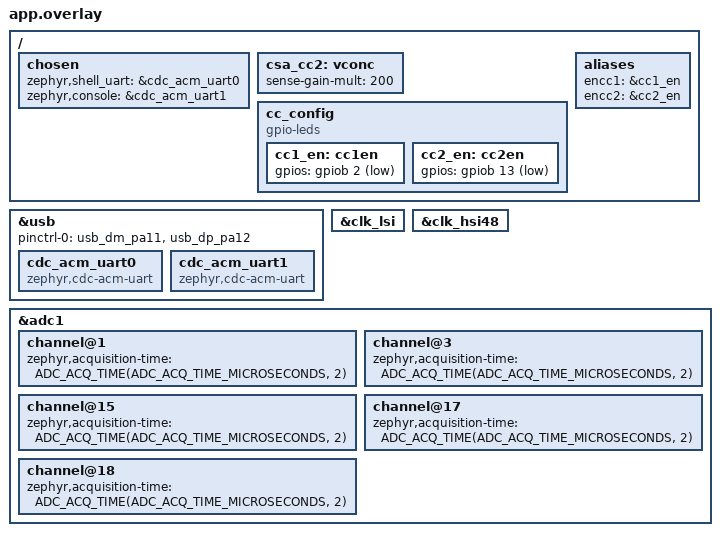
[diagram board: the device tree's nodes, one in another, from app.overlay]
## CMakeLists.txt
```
# Copyright 2023 The ChromiumOS Authors
# Use of this source code is governed by a BSD-style license that can be
# found in the LICENSE file.

set(BOARD google_twinkie_v2)

cmake_minimum_required(VERSION 3.20.5)
find_package(Zephyr REQUIRED HINTS $ENV{ZEPHYR_BASE})

zephyr_include_directories(include)

FILE(GLOB app_sources src/*.c)
target_sources(app PRIVATE ${app_sources})

project(twinkie_v2)
```

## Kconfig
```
# Copyright 2023 The ChromiumOS Authors
# Use of this source code is governed by a BSD-style license that can be
# found in the LICENSE file.

config STM32_UCPD
        bool "USBC TCPC device controller driver"
        depends on SOC_FAMILY_STM32
        default y
	select USE_STM32_LL_BUS
	select USE_STM32_LL_SYSTEM
	select USE_STM32_LL_RCC
	select USE_STM32_LL_DMA
        select USE_STM32_LL_UCPD
	select USE_STM32_LL_USB
	select USE_STM32_HAL_PCD
	select USE_STM32_HAL_PCD_EX
        help
          Enable USBC TCPC support on the STM32 G0, G4, L5, and U5 family of
          processors.

source "Kconfig.zephyr"
```

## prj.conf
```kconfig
# Copyright 2023 The ChromiumOS Authors
# Use of this source code is governed by a BSD-style license that can be
# found in the LICENSE file.

CONFIG_COMPILER_SAVE_TEMPS=y

CONFIG_SMF=y

CONFIG_USB_DEVICE_STACK=y
CONFIG_USB_DEVICE_MANUFACTURER="Google LLC"
CONFIG_USB_DEVICE_PRODUCT="Twinkie V2"
CONFIG_USB_DEVICE_VID=0x18d1
CONFIG_USB_DEVICE_PID=0x5213

CONFIG_USB_DEVICE_STACK=y
CONFIG_USB_COMPOSITE_DEVICE=y
CONFIG_USB_CDC_ACM_RINGBUF_SIZE=512

CONFIG_STDOUT_CONSOLE=y
CONFIG_SERIAL=y
CONFIG_CONSOLE=y
CONFIG_UART_CONSOLE=y
CONFIG_UART_INTERRUPT_DRIVEN=y

CONFIG_PRINTK=y
CONFIG_SHELL=y
CONFIG_SHELL_STACK_SIZE=1024
CONFIG_SHELL_BACKEND_SERIAL=y

CONFIG_THREAD_MONITOR=y
CONFIG_INIT_STACKS=y
CONFIG_BOOT_BANNER=n
CONFIG_THREAD_NAME=y
CONFIG_CBPRINTF_NANO=y

CONFIG_ADC=y
CONFIG_ADC_STM32=y
CONFIG_ADC_SHELL=y
CONFIG_GPIO=y

# A modified version of usb_dc_stm32.c is required.
CONFIG_USB_DC_STM32=n
```

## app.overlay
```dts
/* Copyright 2023 The ChromiumOS Authors
 * Use of this source code is governed by a BSD-style license that can be
 * found in the LICENSE file.
 */

/ {
	chosen {
		zephyr,shell_uart = &cdc_acm_uart0;
		zephyr,console = &cdc_acm_uart1;
	};

        csa_cc2: vconc {
                sense-gain-mult = <200>;
	};

	cc_config {
		compatible = "gpio-leds";
		cc1_en: cc1en {
			gpios = <&gpiob 2 GPIO_ACTIVE_LOW>;
		};

		cc2_en: cc2en {
			gpios = <&gpiob 13 GPIO_ACTIVE_LOW>;
		};
	};

	aliases {
		encc1 = &cc1_en;
		encc2 = &cc2_en;
	};
};

zephyr_udc0: &usb {
	/* Twinkie V2 Command Shell */
	cdc_acm_uart0: cdc_acm_uart0 {
		compatible = "zephyr,cdc-acm-uart";
	};

	/* Twinkie V2 Packet Logging */
	cdc_acm_uart1: cdc_acm_uart1 {
		compatible = "zephyr,cdc-acm-uart";
	};

	pinctrl-0 = <&usb_dm_pa11 &usb_dp_pa12>;
	pinctrl-names = "default";
	status = "okay";
};

&clk_lsi {
	status = "okay";
};

&clk_hsi48 {
	status = "okay";
};

&adc1 {
	channel@1 {
		zephyr,acquisition-time = <ADC_ACQ_TIME(ADC_ACQ_TIME_MICROSECONDS, 2)>;
	};

	channel@3 {
		zephyr,acquisition-time = <ADC_ACQ_TIME(ADC_ACQ_TIME_MICROSECONDS, 2)>;
	};

	channel@15 {
		zephyr,acquisition-time = <ADC_ACQ_TIME(ADC_ACQ_TIME_MICROSECONDS, 2)>;
	};

	channel@17 {
		zephyr,acquisition-time = <ADC_ACQ_TIME(ADC_ACQ_TIME_MICROSECONDS, 2)>;
	};

	channel@18 {
		zephyr,acquisition-time = <ADC_ACQ_TIME(ADC_ACQ_TIME_MICROSECONDS, 2)>;
	};
};
```

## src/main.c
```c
/* Copyright 2023 The ChromiumOS Authors
 * Use of this source code is governed by a BSD-style license that can be
 * found in the LICENSE file.
 */

#include <zephyr/kernel.h>
#include <zephyr/smf.h>
#include <zephyr/drivers/gpio.h>

#include <zephyr/logging/log.h>
#include <zephyr/usb/usb_device.h>
#include <zephyr/device.h>
#include <zephyr/drivers/uart.h>
#include <zephyr/shell/shell.h>

#include "controls.h"
#include "meas.h"
#include "view.h"
#include "model.h"

int main(void)
{
	const struct device *dev_pd_analyzer = DEVICE_DT_GET(DT_CHOSEN(zephyr_console));

	if (usb_enable(NULL)) {
		return -1;
	}

	meas_init();
	controls_init();
	model_init(dev_pd_analyzer);
	view_init();

	return 0;
}
```

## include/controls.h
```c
/* Copyright 2023 The ChromiumOS Authors
 * Use of this source code is governed by a BSD-style license that can be
 * found in the LICENSE file.
 */

#ifndef _CONTROLS_H_
#define _CONTROLS_H_

#include <stdbool.h>

/**
 * @brief Initializes the control module, configure both cc enable pins as active
 *
 * @return 0 on success
 */
int controls_init(void);

/**
 * @brief Enables the cc1 pin
 *
 * @param en true for enable, false for disable
 */
void en_cc1(bool en);

/**
 * @brief Enables the cc2 pin
 *
 * @param en true for enable, false for disable
 */
void en_cc2(bool en);
#endif
```

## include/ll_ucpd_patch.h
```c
/* Copyright 2023 The ChromiumOS Authors
 * Use of this source code is governed by a BSD-style license that can be
 * found in the LICENSE file.
 */

/*
 * Patch file for easy removal when the following issue is resolved:
 * LL Function for checking UCPD RxErr Flag is missing #42
 * https://github.com/STMicroelectronics/STM32CubeG0/issues/42
 */

#include "stm32g0xx_ll_ucpd.h"

#ifndef LL_UCPD_PATCH_H
#define LL_UCPD_PATCH_H

/**
 * @brief  Check if Rx error interrupt
 * @rmtoll SR          RXERR         LL_UCPD_IsActiveFlag_RxErr
 * @param  UCPDx UCPD Instance
 * @retval None
 */
__STATIC_INLINE uint32_t LL_UCPD_IsActiveFlag_RxErr(UCPD_TypeDef const *const UCPDx)
{
	return ((READ_BIT(UCPDx->SR, UCPD_SR_RXERR) == UCPD_SR_RXERR) ? 1UL : 0UL);
}

#endif
```

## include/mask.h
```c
/* Copyright 2023 The ChromiumOS Authors
 * Use of this source code is governed by a BSD-style license that can be
 * found in the LICENSE file.
 */

#ifndef _MASK_H_
#define _MASK_H_

/**
 * @defgroup Bitmask for snooper state
 * Bit positions for the bitmask for setting the role,
 * active CC line, and pull resistors of the Twinkie
 * @{
 */
#define snooper_mask_t uint8_t

#define PULL_RESISTOR_BITS (BIT(0) | BIT(1))
#define SINK_BIT           BIT(2)
#define CC1_CHANNEL_BIT    BIT(3)
#define CC2_CHANNEL_BIT    BIT(4)
/** @} */

#endif
```

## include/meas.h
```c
/* Copyright 2023 The ChromiumOS Authors
 * Use of this source code is governed by a BSD-style license that can be
 * found in the LICENSE file.
 */

#ifndef __MEAS_H__
#define __MEAS_H__

/**
 * @brief Initializes the measurement module, sets up all the adc channels through the device tree
 * binding
 *
 * @return 0 on success
 */
int meas_init(void);

/**
 * @brief Measure the voltage on VBUS
 *
 * @param v pointer where VBUS voltage, in millivolts, is stored
 *
 * @return 0 on success
 */
int meas_vbus_v(int32_t *v);

/**
 * @brief Measure the current on VBUS
 *
 * @param c pointer where VBUS current, in milliamperes, is stored
 *
 * @return 0 on success
 */
int meas_vbus_c(int32_t *c);

/**
 * @brief Measure the voltage on CC1
 *
 * @param v pointer where CC1 voltage, in millivolts, is stored
 *
 * @return 0 on success
 */
int meas_cc1_v(int32_t *v);

/**
 * @brief Measure the voltage on CC2
 *
 * @param v pointer where CC2 voltage, in millivolts, is stored
 *
 * @return 0 on success
 */
int meas_cc2_v(int32_t *v);

/**
 * @brief Measure the current on VCON
 *
 * @param c pointer where VCON current, in milliamperes, is stored
 *
 * @return 0 on success
 */
int meas_vcon_c(int32_t *c);

#endif
```

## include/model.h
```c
/* Copyright 2023 The ChromiumOS Authors
 * Use of this source code is governed by a BSD-style license that can be
 * found in the LICENSE file.
 */

#ifndef _MODEL_H_
#define _MODEL_H_

#include <zephyr/kernel.h>
#include "mask.h"

/**
 * @brief Initializes the snooper model
 *
 * @param dev pointer to the Twinkie device
 *
 * @return 0 on success
 */
int model_init(const struct device *dev);

/**
 * @brief Resets the snooper model
 */
void reset_snooper();

/**
 * @brief Sets the role as source or sink, and set the pull up resistor and active cc line if source
 *
 * @param role_mask a bit mask of the role to be set
 */
void set_role(snooper_mask_t role_mask);

/**
 * @brief Starts or stops the snooper by setting the snoop status
 *
 * @param s true for start, false for stop
 */
void start_snooper(bool s);

/**
 * @brief Sets whether the Twinkie will continuously output data when no pd messages are received
 *
 * @param e true for continuous output, false for output on pd messages only
 */
void set_empty_print(bool e);

/**
 * @brief Sets how fast the twinkie will output data when no pd messages are received
 *
 * @param s true for slow output, false for fast output
 */
void set_sleep_time(uint32_t st);

/**
 * @brief Sets whether twinkie automatically turns off when no receiver is connected.
 *
 * @param s true for auto stop, false for continuous output
 */
void set_auto_stop(bool s);

/**
 * @brief Print to shell the current status of the Twinkie
 *
 * @param ret char array for output of status
 */
void print_status(char *ret, int i);

/**
 * @brief Used only for sharing isr
 */
void ucpd_isr(void);

#endif
```

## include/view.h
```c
/* Copyright 2023 The ChromiumOS Authors
 * Use of this source code is governed by a BSD-style license that can be
 * found in the LICENSE file.
 */

#ifndef _VIEW_H_
#define _VIEW_H_

#include "mask.h"

/**
 * @brief Set the cc line that the snooper is monitoring
 *
 * @param vs bitmask that describes which cc lines should be monitored
 *
 * @return 0 on success
 * @return EIO on failure
 */
int view_set_snoop(snooper_mask_t vs);

/**
 * @brief Records the current cc line connection the Twinkie is detecting
 *
 * @param vc bitmask that describes the cc line that is currently connected
 *
 * @return 0 on success
 * @return EIO on failure
 */
int view_set_connection(snooper_mask_t vc);

/**
 * @brief Returns the value of the cc line currently being snooped.
 *
 * @return bitmask for the current view status
 */
snooper_mask_t get_view_snoop();

/**
 * @brief Initializes the snooper view
 *
 * @param dev pointer to the Twinkie device
 *
 * @return 0 on success
 */
int view_init();

#endif
```

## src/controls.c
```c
/* Copyright 2023 The ChromiumOS Authors
 * Use of this source code is governed by a BSD-style license that can be
 * found in the LICENSE file.
 */

#include <zephyr/kernel.h>
#include <zephyr/drivers/gpio.h>

/* The devicetree node identifier for the cc enable pins. */
#define ENCC1_NODE DT_ALIAS(encc1)
#define ENCC2_NODE DT_ALIAS(encc2)

static const struct gpio_dt_spec encc1 = GPIO_DT_SPEC_GET(ENCC1_NODE, gpios);
static const struct gpio_dt_spec encc2 = GPIO_DT_SPEC_GET(ENCC2_NODE, gpios);

void en_cc1(bool en)
{
	gpio_pin_set_dt(&encc1, en);
}

void en_cc2(bool en)
{
	gpio_pin_set_dt(&encc2, en);
}

int controls_init(void)
{
	int ret;

	if (!device_is_ready(encc1.port)) {
		return -EIO;
	}

	if (!device_is_ready(encc2.port)) {
		return -EIO;
	}

	ret = gpio_pin_configure_dt(&encc1, GPIO_OUTPUT_ACTIVE);
	if (ret < 0) {
		return ret;
	}

	ret = gpio_pin_configure_dt(&encc2, GPIO_OUTPUT_ACTIVE);
	if (ret < 0) {
		return ret;
	}

	return 0;
}
```

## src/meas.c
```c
/* Copyright 2023 The ChromiumOS Authors
 * Use of this source code is governed by a BSD-style license that can be
 * found in the LICENSE file.
 */

#include <stdio.h>
#include <zephyr/kernel.h>
#include <zephyr/drivers/adc.h>
#include <zephyr/drivers/adc/voltage_divider.h>
#include <zephyr/drivers/adc/current_sense_amplifier.h>

/* The devicetree node identifier for the adc aliases. */
#define CC1_V_MEAS_NODE  DT_ALIAS(vcc1)
#define CC2_V_MEAS_NODE  DT_ALIAS(vcc2)
#define VBUS_V_MEAS_NODE DT_ALIAS(vbus)
#define VBUS_C_MEAS_NODE DT_ALIAS(cbus)
#define VCON_C_MEAS_NODE DT_ALIAS(ccon)

static const struct voltage_divider_dt_spec adc_cc1_v =
	VOLTAGE_DIVIDER_DT_SPEC_GET(CC1_V_MEAS_NODE);
static const struct voltage_divider_dt_spec adc_cc2_v =
	VOLTAGE_DIVIDER_DT_SPEC_GET(CC2_V_MEAS_NODE);
static const struct voltage_divider_dt_spec adc_vbus_v =
	VOLTAGE_DIVIDER_DT_SPEC_GET(VBUS_V_MEAS_NODE);
static const struct current_sense_amplifier_dt_spec adc_vbus_c =
	CURRENT_SENSE_AMPLIFIER_DT_SPEC_GET(VBUS_C_MEAS_NODE);
static const struct current_sense_amplifier_dt_spec adc_vcon_c =
	CURRENT_SENSE_AMPLIFIER_DT_SPEC_GET(VCON_C_MEAS_NODE);

int meas_vbus_v(int32_t *v)
{
	int ret;
	int32_t sample_buffer = 0;

	/* Structure defining an ADC sampling sequence */
	struct adc_sequence sequence = {
		.buffer = &sample_buffer,
		/* buffer size in bytes, not number of samples */
		.buffer_size = sizeof(sample_buffer),
		.calibrate = false,
		.oversampling = 8
	};
	adc_sequence_init_dt(&adc_vbus_v.port, &sequence);

	ret = adc_read(adc_vbus_v.port.dev, &sequence);
	if (ret != 0) {
		return ret;
	}

	*v = sample_buffer;
	ret = adc_raw_to_millivolts_dt(&adc_vbus_v.port, v);
	if (ret != 0) {
		return ret;
	}

	ret = voltage_divider_scale_dt(&adc_vbus_v, v);
	if (ret != 0) {
		return ret;
	}

	return 0;
}

int meas_vbus_c(int32_t *c)
{
	int ret;
	int32_t sample_buffer = 0;

	/* Structure defining an ADC sampling sequence */
	struct adc_sequence sequence = {
		.buffer = &sample_buffer,
		/* buffer size in bytes, not number of samples */
		.buffer_size = sizeof(sample_buffer),
		.calibrate = true,
	};
	adc_sequence_init_dt(&adc_vbus_c.port, &sequence);

	ret = adc_read(adc_vbus_c.port.dev, &sequence);
	if (ret != 0) {
		return ret;
	}

	*c = sample_buffer;
	ret = adc_raw_to_millivolts_dt(&adc_vbus_c.port, c);
	if (ret != 0) {
		return ret;
	}

	/* prescaling the voltage offset */
	*c -= adc_vbus_c.port.vref_mv / 2;
	current_sense_amplifier_scale_dt(&adc_vbus_c, c);

	return 0;
}

int meas_cc1_v(int32_t *v)
{
	int ret;
	int32_t sample_buffer = 0;

	/* Structure defining an ADC sampling sequence */
	struct adc_sequence sequence = {
		.buffer = &sample_buffer,
		/* buffer size in bytes, not number of samples */
		.buffer_size = sizeof(sample_buffer),
		.calibrate = true,
	};
	adc_sequence_init_dt(&adc_cc1_v.port, &sequence);

	ret = adc_read(adc_cc1_v.port.dev, &sequence);
	if (ret != 0) {
		return ret;
	}

	*v = sample_buffer;
	ret = adc_raw_to_millivolts_dt(&adc_cc1_v.port, v);
	if (ret != 0) {
		return ret;
	}

	return 0;
}

int meas_cc2_v(int32_t *v)
{
	int ret;
	int32_t sample_buffer = 0;

	/* Structure defining an ADC sampling sequence */
	struct adc_sequence sequence = {
		.buffer = &sample_buffer,
		/* buffer size in bytes, not number of samples */
		.buffer_size = sizeof(sample_buffer),
		.calibrate = true,
	};
	adc_sequence_init_dt(&adc_cc2_v.port, &sequence);

	ret = adc_read(adc_cc2_v.port.dev, &sequence);
	if (ret != 0) {
		return ret;
	}

	*v = sample_buffer;
	ret = adc_raw_to_millivolts_dt(&adc_cc2_v.port, v);
	if (ret != 0) {
		return ret;
	}

	return 0;
}

int meas_vcon_c(int32_t *c)
{
	int ret;
	int32_t sample_buffer = 0;

	/* Structure defining an ADC sampling sequence */
	struct adc_sequence sequence = {
		.buffer = &sample_buffer,
		/* buffer size in bytes, not number of samples */
		.buffer_size = sizeof(sample_buffer),
		.calibrate = true,
	};
	adc_sequence_init_dt(&adc_vcon_c.port, &sequence);

	ret = adc_read(adc_vcon_c.port.dev, &sequence);
	if (ret != 0) {
		return ret;
	}

	*c = sample_buffer;
	ret = adc_raw_to_millivolts_dt(&adc_vcon_c.port, c);
	if (ret != 0) {
		return ret;
	}

	current_sense_amplifier_scale_dt(&adc_vcon_c, c);

	return 0;
}

int meas_init(void)
{
	int ret;

	ret = adc_channel_setup_dt(&adc_cc1_v.port);
	if (ret != 0) {
		return ret;
	}

	ret = adc_channel_setup_dt(&adc_cc2_v.port);
	if (ret != 0) {
		return ret;
	}

	ret = adc_channel_setup_dt(&adc_vbus_v.port);
	if (ret != 0) {
		return ret;
	}

	ret = adc_channel_setup_dt(&adc_vbus_c.port);
	if (ret != 0) {
		return ret;
	}

	ret = adc_channel_setup_dt(&adc_vcon_c.port);
	if (ret != 0) {
		return ret;
	}

	return 0;
}
```

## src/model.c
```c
/* Copyright 2023 The ChromiumOS Authors
 * Use of this source code is governed by a BSD-style license that can be
 * found in the LICENSE file.
 */

#include <stdio.h>
#include <string.h>
#include <zephyr/kernel.h>
#include <zephyr/drivers/gpio.h>
#include <zephyr/drivers/uart.h>
#include <zephyr/sys/ring_buffer.h>

#include <stm32g0xx_ll_bus.h>
#include <stm32g0xx_ll_system.h>
#include <stm32g0xx_ll_dma.h>
#include <stm32g0xx_ll_rcc.h>
#include <stm32g0xx_ll_gpio.h>
#include <stm32g0xx_ll_ucpd.h>

#include "meas.h"
#include "controls.h"
#include "view.h"
#include "model.h"

#include "ll_ucpd_patch.h"

/* STM32 interrupt registers */
#define UCPD_IRQ           8
#define DMA1_CHANNEL1_IRQ  9
#define DMA1_CHANNEL1_PRIO 2
#define UCPD_PRIO          2

/* snooper model thread parameters */
#define MODEL_THREAD_STACK_SIZE 500
#define MODEL_THREAD_PRIORITY   5

/* STM32 UCPD parameters */
static LL_UCPD_InitTypeDef ucpd_params;

/* Byte size of various portions of the packet */
#define MOD_BUFFERS          40
#define PACKET_HEADER_LEN    20
#define PD_SAMPLES           492
#define PACKET_BYTE_SIZE     (PACKET_HEADER_LEN + PD_SAMPLES)
#define MAX_PACKET_XFER_SIZE 64

/* container for information of the type of packet to be sent */
struct packet_type_t {
	uint16_t unused1: 4;
	uint16_t polarity: 2;
	uint16_t lost: 1;
	uint16_t partial: 1;
	uint16_t version: 4;
	uint16_t type: 4;
};

/* container for header of the packet */
struct header_t {
	uint32_t sequence;
	uint16_t cc1_voltage;
	uint16_t cc2_voltage;
	uint16_t vcon_current;
	uint16_t vbus_voltage;
	uint16_t vbus_current;
	struct packet_type_t packet_type;
	uint16_t data_len;
	uint16_t unused;
};

/* container for the entire packet */
struct packet_t {
	struct header_t header;
	uint8_t data[PD_SAMPLES];
};

/* storage for all the information of the current state of the snooper */
static struct model_t {
	const struct device *dev;
	struct packet_t packet;
	uint8_t dma_buffer[PD_SAMPLES];
	k_tid_t tid;
	bool start;
	bool empty_print;
	bool slow_print;
	bool auto_stop;

	uint8_t mod_buff[MOD_BUFFERS][PD_SAMPLES];
	uint16_t mod_size[MOD_BUFFERS];
	struct packet_type_t sop[MOD_BUFFERS];
	uint8_t mw;
	uint8_t mr;
	uint32_t sleep_time;
} model;

K_THREAD_STACK_DEFINE(model_stack_area, MODEL_THREAD_STACK_SIZE);
static struct k_thread model_thread_data;
static int pd_line;

void start_snooper(bool s)
{
	model.start = s;
	if (s) {
		model.packet.header.sequence = 0;
		view_set_snoop(CC1_CHANNEL_BIT | CC2_CHANNEL_BIT);
	} else {
		view_set_snoop(0);
	}
}

void reset_snooper()
{
	memset(&model.mod_buff, 0, MOD_BUFFERS * PD_SAMPLES);
	memset(&model.mod_size, 0, MOD_BUFFERS * sizeof(uint16_t));
	memset(&model.sop, 0, MOD_BUFFERS * sizeof(uint16_t));
	model.mr = 0;
	model.mw = 0;
	model.packet.header.sequence = 0;
}

void set_role(snooper_mask_t role_mask)
{
	if (role_mask & SINK_BIT) {
		LL_UCPD_SetccEnable(UCPD1, LL_UCPD_CCENABLE_CC1CC2);
		LL_UCPD_SetSNKRole(UCPD1);
		return;
	}

	if (role_mask & CC1_CHANNEL_BIT) {
		LL_UCPD_SetccEnable(UCPD1, LL_UCPD_CCENABLE_CC1);
	} else if (role_mask & CC2_CHANNEL_BIT) {
		LL_UCPD_SetccEnable(UCPD1, LL_UCPD_CCENABLE_CC2);
	}
	LL_UCPD_SetSRCRole(UCPD1);

	uint8_t Rp = role_mask & PULL_RESISTOR_BITS;

	switch (Rp) {
	case 0:
		LL_UCPD_SetRpResistor(UCPD1, LL_UCPD_RESISTOR_NONE);
		break;
	case 1:
		LL_UCPD_SetRpResistor(UCPD1, LL_UCPD_RESISTOR_DEFAULT);
		break;
	case 2:
		LL_UCPD_SetRpResistor(UCPD1, LL_UCPD_RESISTOR_1_5A);
		break;
	case 3:
		LL_UCPD_SetRpResistor(UCPD1, LL_UCPD_RESISTOR_3_0A);
	}
}

void set_empty_print(bool e)
{
	model.empty_print = e;
}

void set_sleep_time(uint32_t st)
{
	model.sleep_time = st;
}

void set_auto_stop(bool s)
{
	model.auto_stop = s;
}

void print_status(char *ret, int i)
{
	switch (i) {
	case 0:
		sprintf(ret, "Twinkie status: %s", model.start ? "on" : "off");
		break;
	case 1:
		sprintf(ret, "Current packet number: %i", model.packet.header.sequence);
		break;
	}
}

#define CC_VOLTAGE_LOW  500
#define CC_VOLTAGE_HIGH 2000

static void model_thread(void *arg1, void *arg2, void *arg3)
{
	int32_t vbus_v, vbus_c;
	int32_t vcon_c;
	int32_t cc1_v, cc2_v;
	struct model_t *sm = (struct model_t *)arg1;

	while (1) {
		if (sm->start) {
			sm->packet.header.sequence++;

			if (sm->packet.header.sequence % 10 == 0) {
				meas_vbus_v(&vbus_v);
				meas_vbus_c(&vbus_c);
				meas_cc1_v(&cc1_v);
				meas_cc2_v(&cc2_v);
				meas_vcon_c(&vcon_c);

				/* because the twinkie itself is a port, detecting a
				 * valid connection through the UCPD line will cause
				 * false positives. e.g. if the line being snooped is a
				 * source to source connection and the twinkie is set as
				 * a sink, the twinkie UCPD will incorrectly detect a
				 * valid connection. So the connection has to be
				 * detected using the ADC pins.
				 */
				if ((cc1_v < CC_VOLTAGE_HIGH) && (cc1_v > CC_VOLTAGE_LOW)) {
					/*connect to non-active line if the active line is not set
					 * to view*/
					if (get_view_snoop() & CC1_CHANNEL_BIT) {
						LL_UCPD_SetCCPin(UCPD1, LL_UCPD_CCPIN_CC1);
					} else {
						LL_UCPD_SetCCPin(UCPD1, LL_UCPD_CCPIN_CC2);
					}
					view_set_connection(CC1_CHANNEL_BIT);
					pd_line = 1;
				} else if ((cc2_v < CC_VOLTAGE_HIGH) && (cc2_v > CC_VOLTAGE_LOW)) {
					/*connect to non-active line if the active line is not set
					 * to view*/
					if (get_view_snoop() & CC2_CHANNEL_BIT) {
						LL_UCPD_SetCCPin(UCPD1, LL_UCPD_CCPIN_CC2);
					} else {
						LL_UCPD_SetCCPin(UCPD1, LL_UCPD_CCPIN_CC1);
					}
					view_set_connection(CC2_CHANNEL_BIT);
					pd_line = 2;
				} else {
					view_set_connection(0);
				}
			}
			if (sm->packet.header.sequence % 10 < 8) {
				sm->packet.header.vbus_voltage = vbus_v;
				sm->packet.header.vbus_current = vbus_c;
				sm->packet.header.cc1_voltage = cc1_v;
				sm->packet.header.cc2_voltage = cc2_v;
				sm->packet.header.vcon_current = vcon_c;

				/* put pd message in the packet if any are stored */
				if (sm->mw != sm->mr) {
					sm->packet.header.packet_type = sm->sop[sm->mr];
					sm->packet.header.data_len = sm->mod_size[sm->mr];
					memcpy(sm->packet.data, sm->mod_buff[sm->mr],
					       sm->mod_size[sm->mr]);
					memset((uint8_t *)&sm->sop[sm->mr], 0, sizeof(uint16_t));
					sm->mod_size[sm->mr] = 0;
					memset(sm->mod_buff[sm->mr], 0, PD_SAMPLES);
					sm->mr++;
					if (sm->mr == MOD_BUFFERS) {
						sm->mr = 0;
					}
				}

				if (sm->empty_print || sm->packet.header.data_len != 0) {
					int stop_timer = 0;
					for (int i = 0, w = 0; i < PACKET_BYTE_SIZE; i += w) {
						w = uart_fifo_fill(sm->dev,
								   (const uint8_t *)&sm->packet + i,
								   PACKET_BYTE_SIZE - i);
						if (w <= 0) {
							stop_timer++;
							k_usleep(sm->sleep_time);
							if (stop_timer > 100 && sm->auto_stop) {
								start_snooper(false);
								break;
							}
						}
					}
				}
				memset(sm->packet.data, 0, PD_SAMPLES);
				sm->packet.header.data_len = 0;
			}
		}
		if (sm->mw == sm->mr) {
			k_usleep(sm->sleep_time);
		}
	}
}

#define MY_DEV_IRQ   12
#define MY_DEV_PRIO  2
#define MY_ISR_ARG   NULL
#define MY_IRQ_FLAGS 0

void ucpd_isr(void)
{
	struct model_t *sm = &model;

	/* TypeCEvent flag currently not used */
	if (LL_UCPD_IsActiveFlag_TypeCEventCC1(UCPD1) ||
	    LL_UCPD_IsActiveFlag_TypeCEventCC2(UCPD1)) {
		LL_UCPD_ClearFlag_TypeCEventCC1(UCPD1);
		LL_UCPD_ClearFlag_TypeCEventCC2(UCPD1);
	}

	if (LL_UCPD_IsActiveFlag_RxErr(UCPD1)) {
		LL_DMA_DisableChannel(DMA1, LL_DMA_CHANNEL_1);
		LL_DMA_SetDataLength(DMA1, LL_DMA_CHANNEL_1, PD_SAMPLES);
		memcpy(sm->mod_buff[sm->mw], sm->dma_buffer, PD_SAMPLES);
		memset(sm->dma_buffer, 0, PD_SAMPLES);
		sm->mod_size[sm->mw] = LL_UCPD_ReadRxPaySize(UCPD1);
		sm->sop[sm->mr].type = LL_UCPD_ReadRxOrderSet(UCPD1);
		sm->sop[sm->mw].polarity = pd_line;
		sm->sop[sm->mw].partial = true;
		sm->mw++;
		if (sm->mw == MOD_BUFFERS) {
			sm->mw = 0;
		}
		LL_DMA_EnableChannel(DMA1, LL_DMA_CHANNEL_1);
		k_wakeup(sm->tid);
	}

	if (LL_UCPD_IsActiveFlag_RxMsgEnd(UCPD1)) {
		LL_DMA_DisableChannel(DMA1, LL_DMA_CHANNEL_1);
		LL_DMA_SetDataLength(DMA1, LL_DMA_CHANNEL_1, PD_SAMPLES);
		memcpy(sm->mod_buff[sm->mw], sm->dma_buffer, PD_SAMPLES);
		memset(sm->dma_buffer, 0, PD_SAMPLES);
		sm->mod_size[sm->mw] = LL_UCPD_ReadRxPaySize(UCPD1);
		sm->sop[sm->mr].type = LL_UCPD_ReadRxOrderSet(UCPD1);
		sm->sop[sm->mw].polarity = pd_line;
		sm->sop[sm->mw].partial = false;
		sm->mw++;
		if (sm->mw == MOD_BUFFERS) {
			sm->mw = 0;
		}
		LL_DMA_EnableChannel(DMA1, LL_DMA_CHANNEL_1);
		k_wakeup(sm->tid);
		LL_UCPD_ClearFlag_RxMsgEnd(UCPD1);
	}
}

static void update_stm32g0x_cc_line(void)
{
	SYSCFG->CFGR1 |= SYSCFG_CFGR1_UCPD1_STROBE_Msk;
}

enum pd_cc_t {
	PD_OFF,
	PD_BOTH,
	PD_CC1,
	PD_CC2
};

static void pd_on_cc(enum pd_cc_t p)
{
	switch (p) {
	case PD_OFF:
		LL_UCPD_TypeCDetectionCC1Disable(UCPD1);
		LL_UCPD_TypeCDetectionCC2Disable(UCPD1);
		break;
	case PD_BOTH:
		LL_UCPD_TypeCDetectionCC1Enable(UCPD1);
		LL_UCPD_TypeCDetectionCC2Enable(UCPD1);
		break;
	case PD_CC1:
		LL_UCPD_TypeCDetectionCC2Disable(UCPD1);
		LL_UCPD_TypeCDetectionCC1Enable(UCPD1);
		break;
	case PD_CC2:
		LL_UCPD_TypeCDetectionCC1Disable(UCPD1);
		LL_UCPD_TypeCDetectionCC2Enable(UCPD1);
		break;
	}
}

int model_init(const struct device *dev)
{
	int ret;

	model.dev = dev;
	model.mw = 0;
	model.mr = 0;

	update_stm32g0x_cc_line();

	/** Configure CC pins */

	/* Set PIN A8 as analog */
	LL_GPIO_SetPinMode(GPIOA, LL_GPIO_PIN_8, LL_GPIO_MODE_ANALOG);

	/* Set PIN B15 as analog */
	LL_GPIO_SetPinMode(GPIOB, LL_GPIO_PIN_15, LL_GPIO_MODE_ANALOG);

	/** Configure DMA */

	/* DMA CLOCK */
	LL_AHB1_GRP1_EnableClock(LL_AHB1_GRP1_PERIPH_DMA1);

	LL_DMA_DisableChannel(DMA1, LL_DMA_CHANNEL_1);

	LL_DMA_ConfigTransfer(DMA1, LL_DMA_CHANNEL_1, LL_DMA_DIRECTION_PERIPH_TO_MEMORY);

	/* DMA from UCPD RXDR register */
	LL_DMA_ConfigAddresses(DMA1, LL_DMA_CHANNEL_1, (uint32_t)&UCPD1->RXDR,
			       (uint32_t)model.dma_buffer, LL_DMA_DIRECTION_PERIPH_TO_MEMORY);

	LL_DMA_SetMode(DMA1, LL_DMA_CHANNEL_1, LL_DMA_MODE_NORMAL);

	LL_DMA_SetPeriphIncMode(DMA1, LL_DMA_CHANNEL_1, LL_DMA_PERIPH_NOINCREMENT);

	LL_DMA_SetMemoryIncMode(DMA1, LL_DMA_CHANNEL_1, LL_DMA_MEMORY_INCREMENT);

	LL_DMA_SetPeriphSize(DMA1, LL_DMA_CHANNEL_1, LL_DMA_PDATAALIGN_BYTE);

	LL_DMA_SetMemorySize(DMA1, LL_DMA_CHANNEL_1, LL_DMA_MDATAALIGN_BYTE);

	LL_DMA_SetChannelPriorityLevel(DMA1, LL_DMA_CHANNEL_1, LL_DMA_PRIORITY_VERYHIGH);

	LL_DMA_SetDataLength(DMA1, LL_DMA_CHANNEL_1, PD_SAMPLES);

	LL_DMA_SetPeriphRequest(DMA1, LL_DMA_CHANNEL_1, LL_DMAMUX_REQ_UCPD1_RX);

	LL_DMA_EnableChannel(DMA1, LL_DMA_CHANNEL_1);

	model.packet.header.sequence = 0;

	/** Configure UCPD */

	ucpd_params.psc_ucpdclk = 0;
	ucpd_params.transwin = 7;
	ucpd_params.IfrGap = 16;
	ucpd_params.HbitClockDiv = 26;

	/*
	 * The UCPD port is disabled in the LL_UCPD_Init function
	 *
	 * NOTE: For proper Power Management operation, this function
	 *       should not be used because it circumvents the zephyr
	 *       clock API. Instead, DTS clock settings and the zephyr
	 *       clock API should be used to enable clocks.
	 */
	ret = LL_UCPD_Init(UCPD1, &ucpd_params);
	if (ret == SUCCESS) {
		/* ORDSET */
		LL_UCPD_SetRxOrderSet(UCPD1, LL_UCPD_ORDERSET_SOP | LL_UCPD_ORDERSET_SOP1 |
						     LL_UCPD_ORDERSET_SOP2 |
						     LL_UCPD_ORDERSET_HARDRST |
						     LL_UCPD_ORDERSET_CABLERST);

		/* ENABLE DMA */
		LL_UCPD_RxDMAEnable(UCPD1);

		/* Enable UCPD port */
		LL_UCPD_Enable(UCPD1);
		start_snooper(false);

		pd_on_cc(PD_BOTH);
		update_stm32g0x_cc_line();

		LL_UCPD_EnableIT_RxNE(UCPD1);

		LL_UCPD_EnableIT_TypeCEventCC1(UCPD1);
		LL_UCPD_EnableIT_TypeCEventCC2(UCPD1);
		LL_UCPD_ClearFlag_TypeCEventCC1(UCPD1);
		LL_UCPD_ClearFlag_TypeCEventCC2(UCPD1);

		LL_UCPD_SetccEnable(UCPD1, LL_UCPD_CCENABLE_CC1CC2);

		LL_UCPD_EnableIT_RxMsgEnd(UCPD1);
		LL_UCPD_ClearFlag_RxMsgEnd(UCPD1);

		LL_UCPD_RxEnable(UCPD1);
	} else {
		return -EIO;
	}

	LL_UCPD_SetSNKRole(UCPD1);

	en_cc1(true);
	en_cc2(true);

	set_auto_stop(true);
	set_empty_print(true);
	set_sleep_time(500);

	model.tid = k_thread_create(&model_thread_data, model_stack_area,
				    K_THREAD_STACK_SIZEOF(model_stack_area), model_thread, &model,
				    NULL, NULL, MODEL_THREAD_PRIORITY, 0, K_NO_WAIT);

	return 0;
}
```

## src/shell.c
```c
/* Copyright 2023 The ChromiumOS Authors
 * Use of this source code is governed by a BSD-style license that can be
 * found in the LICENSE file.
 */

#include <stdlib.h>
#include <zephyr/kernel.h>
#include <zephyr/usb/usb_device.h>
#include <zephyr/device.h>
#include <zephyr/drivers/uart.h>
#include <zephyr/shell/shell.h>
#include <zephyr/drivers/usb/usb_dc.h>

#include "view.h"
#include "meas.h"
#include "model.h"
#include "mask.h"

static int cmd_meas_cc2(const struct shell *shell, size_t argc, char **argv)
{
	int32_t out;

	if (argc == 2 && *argv[1] == 'c') {
		meas_vcon_c(&out);
		shell_print(shell, "current of cc2: %i", out);
	} else {
		meas_cc2_v(&out);
		shell_print(shell, "voltage of cc2: %i", out);
	}

	return 0;
}

static int cmd_meas_vb(const struct shell *shell, size_t argc, char **argv)
{
	int32_t out;

	if (argc == 2 && *argv[1] == 'c') {
		meas_vbus_c(&out);
		shell_print(shell, "current of vbus: %i", out);
	} else {
		meas_vbus_v(&out);
		shell_print(shell, "voltage of vbus: %i", out);
	}

	return 0;
}

static int cmd_meas_cc1(const struct shell *shell, size_t argc, char **argv)
{
	int32_t out;

	meas_cc1_v(&out);
	shell_print(shell, "voltage of cc1: %i", out);

	return 0;
}

SHELL_STATIC_SUBCMD_SET_CREATE(sub_meas, SHELL_CMD(cc1, NULL, "Print cc1 voltage.", cmd_meas_cc1),
			       SHELL_CMD(cc2, NULL, "Print cc2 voltage or current.", cmd_meas_cc2),
			       SHELL_CMD(vb, NULL, "Print vbus voltage or current.", cmd_meas_vb),
			       SHELL_SUBCMD_SET_END);

SHELL_CMD_REGISTER(meas, &sub_meas, "Reads current or voltage of the selected line", NULL);

static int cmd_version(const struct shell *shell, size_t argc, char **argv)
{
	ARG_UNUSED(argc);
	ARG_UNUSED(argv);

	shell_print(shell, "Twinkie version 2.2.2");

	return 0;
}

SHELL_CMD_REGISTER(version, NULL, "Show Twinkie version", cmd_version);

static int cmd_reset(const struct shell *shell, size_t argc, char **argv)
{
	start_snooper(false);
	reset_snooper();
	usb_dc_reset();

	start_snooper(true);
	return 0;
}

SHELL_CMD_REGISTER(reset, NULL, "Resets the Twinkie device", cmd_reset);

static int cmd_snoop(const struct shell *shell, size_t argc, char **argv)
{
	if (argc >= 2) {
		switch (*argv[1]) {
		case '0':
			view_set_snoop(0);
			break;
		case '1':
			view_set_snoop(CC1_CHANNEL_BIT);
			break;
		case '2':
			view_set_snoop(CC2_CHANNEL_BIT);
			break;
		case '3':
			view_set_snoop(CC1_CHANNEL_BIT | CC2_CHANNEL_BIT);
		}
	}

	return 0;
}

SHELL_CMD_REGISTER(snoop, NULL, "Sets the snoop CC line, 0 for neither, 3 for both", cmd_snoop);

static int cmd_start(const struct shell *shell, size_t argc, char **argv)
{
	start_snooper(true);
	return 0;
}
SHELL_CMD_REGISTER(start, NULL, "Start snooper", cmd_start);

static int cmd_stop(const struct shell *shell, size_t argc, char **argv)
{
	usb_dc_reset();
	start_snooper(false);
	return 0;
}
SHELL_CMD_REGISTER(stop, NULL, "Stop snooper", cmd_stop);

static int cmd_role(const struct shell *shell, size_t argc, char **argv, void *data)
{
	snooper_mask_t pull_mask = (uint32_t)data;

	set_role(pull_mask);

	return 0;
}

SHELL_SUBCMD_DICT_SET_CREATE(role_options, cmd_role, (sink, SINK_BIT, "sink"),
			     (source, 0, "source"));

SHELL_CMD_REGISTER(role, &role_options, "Sets role as sink or source", cmd_role);

static int cmd_cc1_pull(const struct shell *shell, size_t argc, char **argv, void *data)
{
	snooper_mask_t pull_mask = (uint32_t)data;

	set_role(pull_mask & CC1_CHANNEL_BIT);

	return 0;
}

static int cmd_cc2_pull(const struct shell *shell, size_t argc, char **argv, void *data)
{
	snooper_mask_t pull_mask = (uint32_t)data;

	set_role(pull_mask & CC2_CHANNEL_BIT);

	return 0;
}

SHELL_SUBCMD_DICT_SET_CREATE(cc1_options, cmd_cc1_pull, (rd, 0, "resistor disconnected"),
			     (ru, 1, "default resistor"), (r1, 2, "1.5A resistor"),
			     (r3, 3, "3A resistor"));

SHELL_SUBCMD_DICT_SET_CREATE(cc2_options, cmd_cc2_pull, (rd, 0, "resistor disconnected"),
			     (ru, 1, "default resistor"), (r1, 2, "1.5A resistor"),
			     (r3, 3, "3A resistor"));

SHELL_STATIC_SUBCMD_SET_CREATE(
	sub_rpull, SHELL_CMD(cc1, &cc1_options, "Sets pull resistor on cc1", cmd_cc1_pull),
	SHELL_CMD(cc2, &cc2_options, "Sets pull resistor on cc2", cmd_cc2_pull),
	SHELL_SUBCMD_SET_END);

SHELL_CMD_REGISTER(rpull, &sub_rpull, "Place pull resistor", NULL);

static int cmd_output(const struct shell *shell, size_t argc, char **argv, void *data)
{
	bool p = (int)data;

	set_empty_print(p);

	return 0;
}

SHELL_SUBCMD_DICT_SET_CREATE(output_options, cmd_output, (cont, true, "continuous output"),
			     (pd_only, false, "output only on receiving pd messages"));

SHELL_CMD_REGISTER(output, &output_options,
		   "Sets console output as continuous or only on receiving PD messages",
		   cmd_output);

static int cmd_auto_stop(const struct shell *shell, size_t argc, char **argv, void *data)
{
	bool p = (bool)data;

	set_auto_stop(p);

	return 0;
}

SHELL_SUBCMD_DICT_SET_CREATE(cmd_auto_stop_options, cmd_auto_stop,
			     (on, true, "twinkie turns off when no reciever is connected"),
			     (off, false,
			      "twinkie continues sending even when there is no response "
			      "from host (WARNING: may cause data corruption or desync)"));

SHELL_CMD_REGISTER(auto_stop, &cmd_auto_stop_options,
		   "Sets to automatically turn off when no valid receiver is connected",
		   cmd_auto_stop);

static int cmd_sleep_time(const struct shell *shell, size_t argc, char **argv, void *data)
{
	if (argc == 2) {
		set_sleep_time(atoi(argv[1]));
		shell_print(shell, "%d", atoi(argv[1]));
	}

	return 0;
}

SHELL_CMD_REGISTER(sleep_time, NULL,
		   "Sets console output as continuous or only on receiving PD messages",
		   cmd_sleep_time);

static int cmd_status(const struct shell *shell, size_t argc, char **argv)
{

	char p[50];

	print_status(p, 0);
	shell_print(shell, "%s", p);
	print_status(p, 1);
	shell_print(shell, "%s", p);

	return 0;
}

SHELL_CMD_REGISTER(status, NULL, "Print the twinkie status", cmd_status);
```

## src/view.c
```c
/* Copyright 2023 The ChromiumOS Authors
 * Use of this source code is governed by a BSD-style license that can be
 * found in the LICENSE file.
 */

#include <zephyr/kernel.h>
#include <zephyr/smf.h>
#include <zephyr/drivers/gpio.h>

#include <zephyr/logging/log.h>
#include <zephyr/usb/usb_device.h>
#include <zephyr/device.h>
#include <zephyr/drivers/uart.h>
#include <zephyr/shell/shell.h>

#include "controls.h"
#include "meas.h"
#include "view.h"
#include "model.h"

LOG_MODULE_REGISTER(main);

#define DEBUG 1

/* The devicetree node identifier for the led aliases. */
#define LED0_NODE DT_ALIAS(led0)
#define LED1_NODE DT_ALIAS(led1)
#define LED2_NODE DT_ALIAS(led2)

/* various flags for the current state of the snooper */
#define FLAGS_SNOOP0         0
#define FLAGS_SNOOP1         1
#define FLAGS_SNOOP2         2
#define FLAGS_SNOOP3         3
#define FLAGS_NO_CONNECTION  4
#define FLAGS_CC1_CONNECTION 5
#define FLAGS_CC2_CONNECTION 6

static const struct gpio_dt_spec led0 = GPIO_DT_SPEC_GET(LED0_NODE, gpios);
static const struct gpio_dt_spec led1 = GPIO_DT_SPEC_GET(LED1_NODE, gpios);
static const struct gpio_dt_spec led2 = GPIO_DT_SPEC_GET(LED2_NODE, gpios);

static const struct smf_state view_states[];

enum led_t {
	LED_OFF,
	LED_RED,
	LED_GREEN,
	LED_BLUE
};
enum view_state_t {
	SNOOP0,
	SNOOP1,
	SNOOP2,
	SNOOP3
};

struct view_obj_t {
	struct smf_ctx ctx;
	k_timeout_t timeout;
	bool toggle;
	atomic_t flags;
} view_obj;

snooper_mask_t get_view_snoop()
{
	if (atomic_test_bit(&view_obj.flags, FLAGS_SNOOP0)) {
		return 0;
	}
	if (atomic_test_bit(&view_obj.flags, FLAGS_SNOOP1)) {
		return CC1_CHANNEL_BIT;
	}
	if (atomic_test_bit(&view_obj.flags, FLAGS_SNOOP2)) {
		return CC2_CHANNEL_BIT;
	}
	if (atomic_test_bit(&view_obj.flags, FLAGS_SNOOP3)) {
		return (CC1_CHANNEL_BIT | CC2_CHANNEL_BIT);
	}
	return 0;
}

int view_set_connection(snooper_mask_t vc)
{
	switch (vc) {
	case 0:
		atomic_clear_bit(&view_obj.flags, FLAGS_CC1_CONNECTION);
		atomic_clear_bit(&view_obj.flags, FLAGS_CC2_CONNECTION);
		atomic_set_bit(&view_obj.flags, FLAGS_NO_CONNECTION);
		break;
	case CC1_CHANNEL_BIT:
		atomic_clear_bit(&view_obj.flags, FLAGS_NO_CONNECTION);
		atomic_clear_bit(&view_obj.flags, FLAGS_CC2_CONNECTION);
		atomic_set_bit(&view_obj.flags, FLAGS_CC1_CONNECTION);
		break;
	case CC2_CHANNEL_BIT:
		atomic_clear_bit(&view_obj.flags, FLAGS_NO_CONNECTION);
		atomic_clear_bit(&view_obj.flags, FLAGS_CC1_CONNECTION);
		atomic_set_bit(&view_obj.flags, FLAGS_CC2_CONNECTION);
		break;
	default:
		return -EIO;
	}
	return 0;
}

int view_set_snoop(snooper_mask_t vs)
{
	switch (vs) {
	case 0:
		atomic_clear_bit(&view_obj.flags, FLAGS_SNOOP1);
		atomic_clear_bit(&view_obj.flags, FLAGS_SNOOP2);
		atomic_clear_bit(&view_obj.flags, FLAGS_SNOOP3);
		atomic_set_bit(&view_obj.flags, FLAGS_SNOOP0);
		break;
	case CC1_CHANNEL_BIT:
		atomic_clear_bit(&view_obj.flags, FLAGS_SNOOP0);
		atomic_clear_bit(&view_obj.flags, FLAGS_SNOOP2);
		atomic_clear_bit(&view_obj.flags, FLAGS_SNOOP3);
		atomic_set_bit(&view_obj.flags, FLAGS_SNOOP1);
		break;
	case CC2_CHANNEL_BIT:
		atomic_clear_bit(&view_obj.flags, FLAGS_SNOOP0);
		atomic_clear_bit(&view_obj.flags, FLAGS_SNOOP1);
		atomic_clear_bit(&view_obj.flags, FLAGS_SNOOP3);
		atomic_set_bit(&view_obj.flags, FLAGS_SNOOP2);
		break;
	case (CC1_CHANNEL_BIT | CC2_CHANNEL_BIT):
		atomic_clear_bit(&view_obj.flags, FLAGS_SNOOP0);
		atomic_clear_bit(&view_obj.flags, FLAGS_SNOOP1);
		atomic_clear_bit(&view_obj.flags, FLAGS_SNOOP2);
		atomic_set_bit(&view_obj.flags, FLAGS_SNOOP3);
		break;
	default:
		return -EIO;
	}

	view_set_connection(0);
	return 0;
}

static void set_led(enum led_t led)
{
	switch (led) {
	case LED_OFF:
		gpio_pin_set_dt(&led0, 0);
		gpio_pin_set_dt(&led1, 0);
		gpio_pin_set_dt(&led2, 0);
		break;
	case LED_RED:
		gpio_pin_set_dt(&led0, 1);
		gpio_pin_set_dt(&led1, 0);
		gpio_pin_set_dt(&led2, 0);
		break;
	case LED_GREEN:
		gpio_pin_set_dt(&led0, 0);
		gpio_pin_set_dt(&led1, 1);
		gpio_pin_set_dt(&led2, 0);
		break;
	case LED_BLUE:
		gpio_pin_set_dt(&led0, 0);
		gpio_pin_set_dt(&led1, 0);
		gpio_pin_set_dt(&led2, 1);
		break;
	}
}

static void snoop0_entry(void *o)
{
	struct view_obj_t *vo = (struct view_obj_t *)o;

	set_led(LED_OFF);
	vo->timeout = K_MSEC(1000);
}

static void snoop0_run(void *o)
{
	struct view_obj_t *vo = (struct view_obj_t *)o;

	if (atomic_test_bit(&vo->flags, FLAGS_SNOOP1)) {
		smf_set_state(SMF_CTX(vo), &view_states[SNOOP1]);
	} else if (atomic_test_bit(&vo->flags, FLAGS_SNOOP2)) {
		smf_set_state(SMF_CTX(vo), &view_states[SNOOP2]);
	} else if (atomic_test_bit(&vo->flags, FLAGS_SNOOP3)) {
		smf_set_state(SMF_CTX(vo), &view_states[SNOOP3]);
	}
}

static void snoop0_exit(void *o)
{
}

static void snoop1_entry(void *o)
{
	struct view_obj_t *vo = (struct view_obj_t *)o;

	vo->timeout = K_MSEC(1000);
}

static void snoop1_run(void *o)
{
	struct view_obj_t *vo = (struct view_obj_t *)o;

	if (atomic_test_bit(&vo->flags, FLAGS_SNOOP0)) {
		smf_set_state(SMF_CTX(vo), &view_states[SNOOP0]);
	} else if (atomic_test_bit(&vo->flags, FLAGS_SNOOP2)) {
		smf_set_state(SMF_CTX(vo), &view_states[SNOOP2]);
	} else if (atomic_test_bit(&vo->flags, FLAGS_SNOOP3)) {
		smf_set_state(SMF_CTX(vo), &view_states[SNOOP3]);
	} else if (atomic_test_bit(&vo->flags, FLAGS_NO_CONNECTION)) {
		if (vo->toggle) {
			set_led(LED_BLUE);
			vo->toggle = false;
		} else {
			set_led(LED_OFF);
			vo->toggle = true;
		}
	} else if (atomic_test_bit(&vo->flags, FLAGS_CC1_CONNECTION)) {
		set_led(LED_GREEN);
	} else if (atomic_test_bit(&vo->flags, FLAGS_CC2_CONNECTION)) {
		set_led(LED_RED);
	}
}

static void snoop1_exit(void *o)
{
	set_led(LED_OFF);
}

static void snoop2_entry(void *o)
{
	struct view_obj_t *vo = (struct view_obj_t *)o;

	vo->timeout = K_MSEC(500);
}

static void snoop2_run(void *o)
{
	struct view_obj_t *vo = (struct view_obj_t *)o;

	if (atomic_test_bit(&vo->flags, FLAGS_SNOOP0)) {
		smf_set_state(SMF_CTX(vo), &view_states[SNOOP0]);
	} else if (atomic_test_bit(&vo->flags, FLAGS_SNOOP1)) {
		smf_set_state(SMF_CTX(vo), &view_states[SNOOP1]);
	} else if (atomic_test_bit(&vo->flags, FLAGS_SNOOP3)) {
		smf_set_state(SMF_CTX(vo), &view_states[SNOOP3]);
	} else if (atomic_test_bit(&vo->flags, FLAGS_NO_CONNECTION)) {
		if (vo->toggle) {
			set_led(LED_BLUE);
			vo->toggle = false;
		} else {
			set_led(LED_OFF);
			vo->toggle = true;
		}
	} else if (atomic_test_bit(&vo->flags, FLAGS_CC1_CONNECTION)) {
		set_led(LED_RED);
	} else if (atomic_test_bit(&vo->flags, FLAGS_CC2_CONNECTION)) {
		set_led(LED_GREEN);
	}
}

static void snoop2_exit(void *o)
{
	set_led(LED_OFF);
}

static void snoop3_entry(void *o)
{
	struct view_obj_t *vo = (struct view_obj_t *)o;

	vo->timeout = K_MSEC(250);
}

static void snoop3_run(void *o)
{
	struct view_obj_t *vo = (struct view_obj_t *)o;

	if (atomic_test_bit(&vo->flags, FLAGS_SNOOP0)) {
		smf_set_state(SMF_CTX(vo), &view_states[SNOOP0]);
	} else if (atomic_test_bit(&vo->flags, FLAGS_SNOOP1)) {
		smf_set_state(SMF_CTX(vo), &view_states[SNOOP1]);
	} else if (atomic_test_bit(&vo->flags, FLAGS_SNOOP2)) {
		smf_set_state(SMF_CTX(vo), &view_states[SNOOP2]);
	} else if (atomic_test_bit(&vo->flags, FLAGS_NO_CONNECTION)) {
		if (vo->toggle) {
			set_led(LED_BLUE);
			vo->toggle = false;
		} else {
			set_led(LED_OFF);
			vo->toggle = true;
		}
	} else if (atomic_test_bit(&vo->flags, FLAGS_CC1_CONNECTION)) {
		set_led(LED_GREEN);
	} else if (atomic_test_bit(&vo->flags, FLAGS_CC2_CONNECTION)) {
		set_led(LED_GREEN);
	}
}

static void snoop3_exit(void *o)
{
	set_led(LED_OFF);
}

static const struct smf_state view_states[] = {
	[SNOOP0] = SMF_CREATE_STATE(snoop0_entry, snoop0_run, snoop0_exit),
	[SNOOP1] = SMF_CREATE_STATE(snoop1_entry, snoop1_run, snoop1_exit),
	[SNOOP2] = SMF_CREATE_STATE(snoop2_entry, snoop2_run, snoop2_exit),
	[SNOOP3] = SMF_CREATE_STATE(snoop3_entry, snoop3_run, snoop3_exit),
};

int view_init(void)
{
	int ret;

	if (!device_is_ready(led0.port)) {
		return -EIO;
	}

	if (!device_is_ready(led1.port)) {
		return -EIO;
	}

	if (!device_is_ready(led2.port)) {
		return -EIO;
	}

	ret = gpio_pin_configure_dt(&led0, GPIO_OUTPUT_ACTIVE);
	if (ret < 0) {
		return ret;
	}

	ret = gpio_pin_configure_dt(&led1, GPIO_OUTPUT_ACTIVE);
	if (ret < 0) {
		return ret;
	}

	ret = gpio_pin_configure_dt(&led2, GPIO_OUTPUT_ACTIVE);
	if (ret < 0) {
		return ret;
	}

	view_obj.flags = ATOMIC_INIT(0);

	smf_set_initial(SMF_CTX(&view_obj), &view_states[SNOOP0]);

	while (1) {
		smf_run_state(SMF_CTX(&view_obj));
		k_sleep(view_obj.timeout);
	}
	return 0;
}
```
